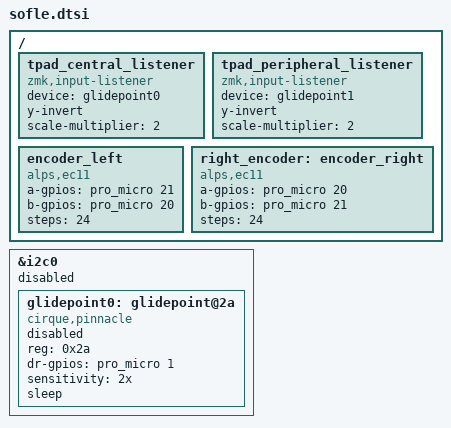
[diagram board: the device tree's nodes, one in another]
&i2c0 {
    status = "disabled";
    glidepoint0: glidepoint@2a {
        compatible = "cirque,pinnacle";
        reg = <0x2a>;
        status = "disabled";
        dr-gpios = <&pro_micro 1 (GPIO_ACTIVE_HIGH)>;

        sensitivity = "2x";
        sleep;
        //no-taps;
    };
};


/ {
	/* assign `input-listener` to all pointing devices */
	/* &glidepoint0 on central, &glidepoint1 on peripheral */
    tpad_central_listener {
        compatible = "zmk,input-listener";
        device = <&glidepoint0>;
        //xy-swap;
        y-invert;
        //x-invert;
        scale-multiplier = <2>;
	};

    tpad_peripheral_listener {
        compatible = "zmk,input-listener";
        device = <&glidepoint1>;
        //xy-swap;
        y-invert;
        //x-invert;
        scale-multiplier = <2>;
    };
	 sensors     
	left_encoder: encoder_left {
        compatible = "alps,ec11";
        a-gpios = <&pro_micro 21 (GPIO_ACTIVE_HIGH | GPIO_PULL_UP)>;
        b-gpios = <&pro_micro 20 (GPIO_ACTIVE_HIGH | GPIO_PULL_UP)>;
        steps = <24>;
    };

    right_encoder: encoder_right {
        compatible = "alps,ec11";
        a-gpios = <&pro_micro 20 (GPIO_ACTIVE_HIGH | GPIO_PULL_UP)>;
        b-gpios = <&pro_micro 21 (GPIO_ACTIVE_HIGH | GPIO_PULL_UP)>;
        steps = <24>;
    };
};
